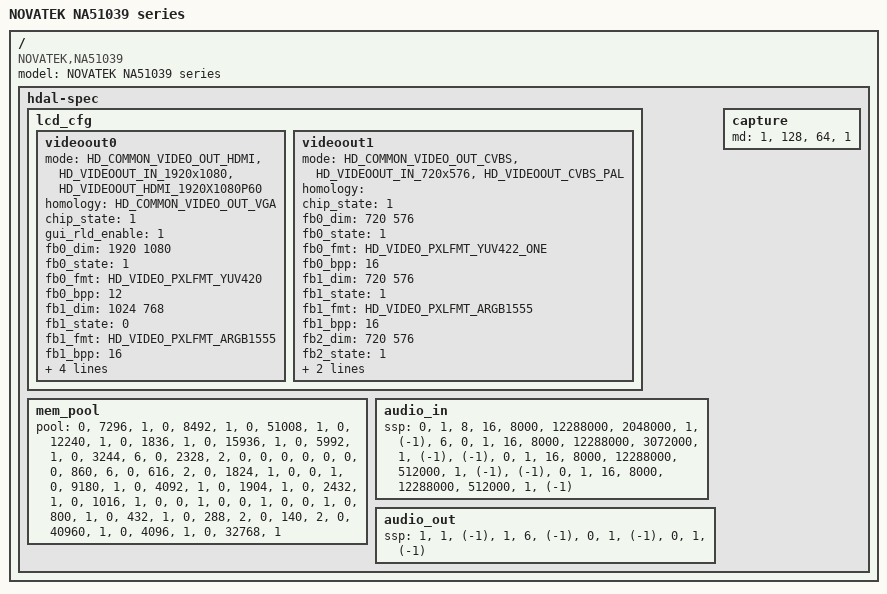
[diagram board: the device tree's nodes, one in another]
# 1 "cfg_DVR_FPGA.dts"
# 1 "<built-in>"
# 1 "<command-line>"
# 1 "cfg_DVR_FPGA.dts"





/dts-v1/;
/{
 model = "NOVATEK NA51039 series";
 compatible = "NOVATEK,NA51039";
 #address-cells = <1>;
 #size-cells = <1>;

 hdal-spec {
 #address-cells = <2>;
 #size-cells = <1>;
  lcd_cfg {
   videoout0 {
    mode = "HD_COMMON_VIDEO_OUT_HDMI","HD_VIDEOOUT_IN_1920x1080","HD_VIDEOOUT_HDMI_1920X1080P60";
    homology = "HD_COMMON_VIDEO_OUT_VGA";
    chip_state = <1>;
    gui_rld_enable = <1>;
    fb0_dim = <1920 1080>;
    fb0_state = <1>;
    fb0_fmt = "HD_VIDEO_PXLFMT_YUV420";
    fb0_bpp = <12>;
    fb1_dim = <1024 768>;
    fb1_state = <0>;
    fb1_fmt = "HD_VIDEO_PXLFMT_ARGB1555";
    fb1_bpp = <16>;
    fb2_dim = <1920 1080>;
    fb2_state = <1>;
    fb2_fmt = "HD_VIDEO_PXLFMT_I4";
    fb2_bpp = <4>;
   };
   videoout1 {
    mode = "HD_COMMON_VIDEO_OUT_CVBS", "HD_VIDEOOUT_IN_720x576", "HD_VIDEOOUT_CVBS_PAL";
    homology = "";
    chip_state = <1>;
    fb0_dim = <720 576>;
    fb0_state = <1>;
    fb0_fmt = "HD_VIDEO_PXLFMT_YUV422_ONE";
    fb0_bpp = <16>;
    fb1_dim = <720 576>;
    fb1_state = <1>;
    fb1_fmt = "HD_VIDEO_PXLFMT_ARGB1555";
    fb1_bpp = <16>;
    fb2_dim = <720 576>;
    fb2_state = <1>;
    fb2_fmt = "HD_VIDEO_PXLFMT_I4";
    fb2_bpp = <4>;
   };

  };
  mem_pool {

   pool =
    <0>, "HD_COMMON_MEM_COMMON_POOL                " , <7296 >,<1 >, "",
    <0>, "HD_COMMON_MEM_DISP_DEC_IN_POOL           " , <8492 >,<1 >, "",
    <0>, "HD_COMMON_MEM_DISP_DEC_OUT_POOL          " , <51008 >,<1 >, "HD_COMMON_MEM_DISP0_CAP_OUT_POOL",
    <0>, "HD_COMMON_MEM_DISP_DEC_OUT_RATIO_POOL    " , <12240 >,<1 >, "",
    <0>, "HD_COMMON_MEM_DEC_TILE_POOL              " , <1836 >,<1 >, "",
    <0>, "HD_COMMON_MEM_ENC_CAP_OUT_POOL           " , <15936 >,<1 >, "",
    <0>, "HD_COMMON_MEM_ENC_OUT_POOL               " , <5992 >,<1 >, "",
    <0>, "HD_COMMON_MEM_ENC_REF_POOL               " , <3244 >,<6 >, "",
    <0>, "HD_COMMON_MEM_ENC_REF_POOL               " , <2328 >,<2 >, "",
    <0>, "HD_COMMON_MEM_ENC_REF_POOL               " , <0 >,<0 >, "",
    <0>, "HD_COMMON_MEM_ENC_REF_POOL               " , <0 >,<0 >, "",
    <0>, "HD_COMMON_MEM_ENC_REF_POOL               " , <860 >,<6 >, "",
    <0>, "HD_COMMON_MEM_ENC_REF_POOL               " , <616 >,<2 >, "",
    <0>, "HD_COMMON_MEM_ENC_SCL_OUT_POOL           " , <1824 >,<1 >, "",
    <0>, "HD_COMMON_MEM_DISP0_CAP_OUT_POOL         " , <0 >,<1 >, "",
    <0>, "HD_COMMON_MEM_DISP0_IN_POOL              " , <9180 >,<1 >, "",
    <0>, "HD_COMMON_MEM_DISP0_FB_POOL              " , <4092 >,<1 >, "",
    <0>, "HD_COMMON_MEM_DISP1_CAP_OUT_POOL         " , <1904 >,<1 >, "",
    <0>, "HD_COMMON_MEM_DISP1_IN_POOL              " , <2432 >,<1 >, "",
    <0>, "HD_COMMON_MEM_DISP1_FB_POOL              " , <1016 >,<1 >, "",
    <0>, "HD_COMMON_MEM_DISP2_CAP_OUT_POOL         " , <0 >,<1 >, "",
    <0>, "HD_COMMON_MEM_DISP2_IN_POOL              " , <0 >,<1 >, "",
    <0>, "HD_COMMON_MEM_DISP2_FB_POOL              " , <0 >,<1 >, "",
    <0>, "HD_COMMON_MEM_AU_ENC_AU_GRAB_OUT_POOL    " , <800 >,<1 >, "",
    <0>, "HD_COMMON_MEM_AU_DEC_AU_RENDER_IN_POOL   " , <432 >,<1 >, "",
    <0>, "HD_COMMON_MEM_GLOBAL_MD_POOL             " , <288 >,<2 >, "",
    <0>, "HD_COMMON_MEM_TMNR_MOTION_POOL           " , <140 >,<2 >, "",
    <0>, "HD_COMMON_MEM_CNN_POOL                   " , <40960 >,<1 >, "",
    <0>, "HD_COMMON_MEM_OSG_POOL                   " , <4096 >,<1 >, "",
    <0>, "HD_COMMON_MEM_USER_BLK                   " , <32768 >,<1 >, "";

  };
  audio_in {

   ssp =
    <0 >, <1 >,<8 >,<16 >,<8000 >,<12288000 >,<2048000 >, <1 >,< (-1) >,
    <6 >, <0 >,<1 >,<16 >,<8000 >,<12288000 >,<3072000 >, <1 >,< (-1) >,
    <(-1) >, <0 >,<1 >,<16 >,<8000 >,<12288000 >,<512000 >, <1 >,< (-1) >,
    <(-1) >, <0 >,<1 >,<16 >,<8000 >,<12288000 >,<512000 >, <1 >,< (-1) >;
  };
  audio_out {

   ssp =
    <1 >, <1 >,< (-1) >,
    <1 >, <6 >,< (-1) >,
    <0 >, <1 >,< (-1) >,
    <0 >, <1 >,< (-1) >;
  };
  capture {
   md =
    <1>, <128>, <64>, <1>;

  };
 };
};
